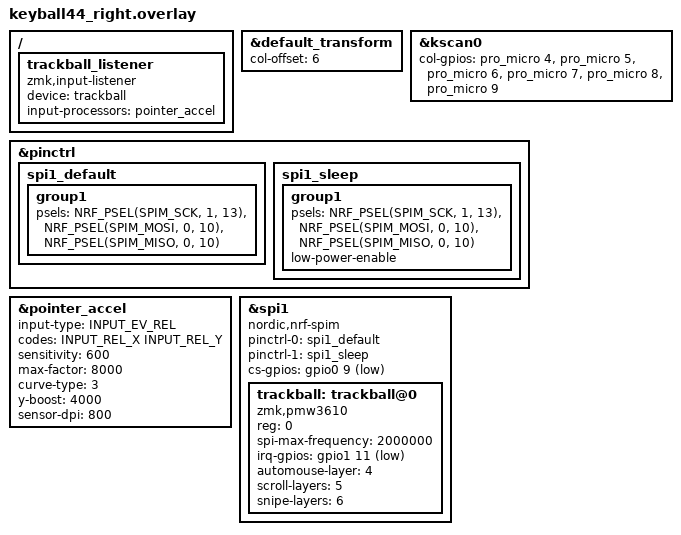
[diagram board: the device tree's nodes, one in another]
/*
 * Copyright (c) 2020 ZMK Contributors
 *
 * SPDX-License-Identifier: MIT
 */
 
#include "keyball44.dtsi"
#include <input/processors.dtsi>
#include <behaviors/input_gestures_accel.dtsi>

&default_transform {
    col-offset = <6>;
};

&kscan0 {
	col-gpios
		= <&pro_micro 4 GPIO_ACTIVE_HIGH>
		, <&pro_micro 5 GPIO_ACTIVE_HIGH>
		, <&pro_micro 6 GPIO_ACTIVE_HIGH>
		, <&pro_micro 7 GPIO_ACTIVE_HIGH>
		, <&pro_micro 8 GPIO_ACTIVE_HIGH>
        , <&pro_micro 9 GPIO_ACTIVE_HIGH>
		;
};

&pinctrl {
    spi1_default: spi1_default {
        group1 {
            psels = <NRF_PSEL(SPIM_SCK, 1, 13)>,
                <NRF_PSEL(SPIM_MOSI, 0, 10)>,
                <NRF_PSEL(SPIM_MISO, 0, 10)>;
        };
    };

    spi1_sleep: spi1_sleep {
        group1 {
            psels = <NRF_PSEL(SPIM_SCK, 1, 13)>,
                <NRF_PSEL(SPIM_MOSI, 0, 10)>,
                <NRF_PSEL(SPIM_MISO, 0, 10)>;
            low-power-enable;
        };
    };
};

&pointer_accel {
    input-type = <INPUT_EV_REL>;
    codes = <INPUT_REL_X INPUT_REL_Y>;
    sensitivity = <600>;     // 1.3x base sensitivity
    max-factor = <8000>;      // 2.8x maximum acceleration (capped at 3.0x for safety)
    curve-type = <3>;         // 0=Linear, 1=Mild, 2=Strong
    y-boost = <4000>;         // 1.2x Y-axis boost (optional, defaults to 1000)
    sensor-dpi = <800>;       // 800 DPI sensor (optional, defaults to 800)
};

&spi1 {
    status = "okay";
    compatible = "nordic,nrf-spim";
    pinctrl-0 = <&spi1_default>;
    pinctrl-1 = <&spi1_sleep>;
    pinctrl-names = "default", "sleep";
    cs-gpios = <&gpio0 9 GPIO_ACTIVE_LOW>;

    trackball: trackball@0 {
        status = "okay";
        compatible = "zmk,pmw3610";
        reg = <0>;
        spi-max-frequency = <2000000>;
        irq-gpios = <&gpio1 11 (GPIO_ACTIVE_LOW | GPIO_PULL_UP)>;
	automouse-layer = <4>;
	scroll-layers = <5>;
	snipe-layers = <6>;
    };
};

/ {
  trackball_listener {
    compatible = "zmk,input-listener";
    device = <&trackball>;
	input-processors = <
		&pointer_accel      // Acceleration processor
	>;
  };
};
